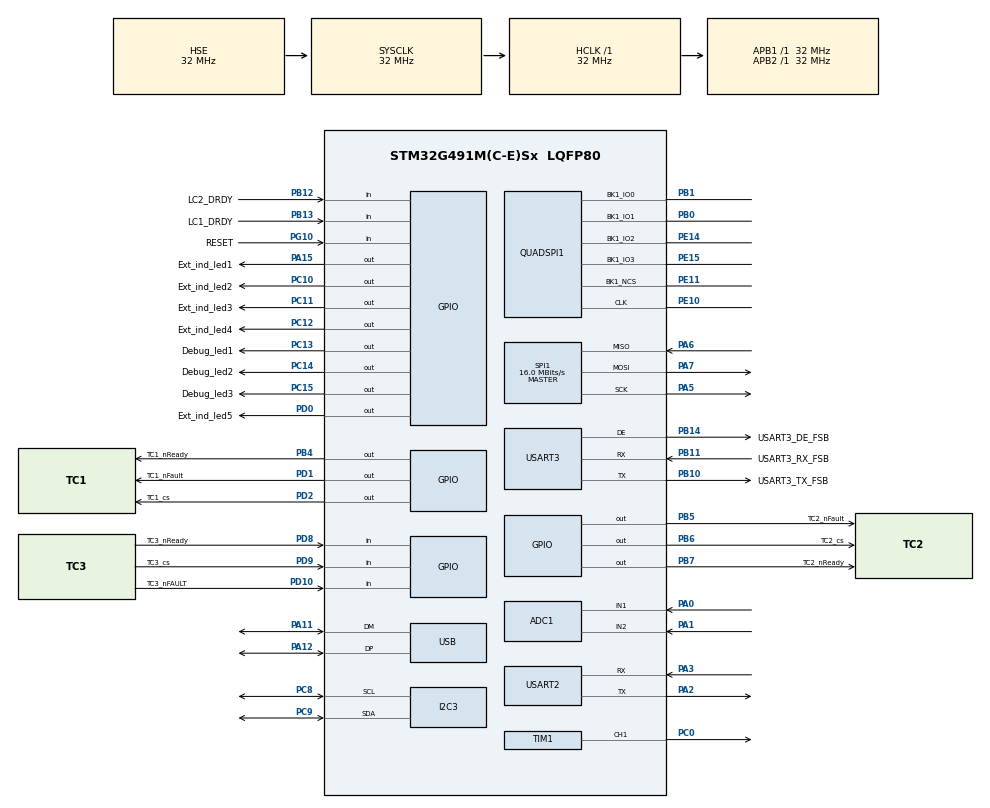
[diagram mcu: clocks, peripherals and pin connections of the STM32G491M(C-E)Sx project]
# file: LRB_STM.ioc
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ADC1.Channel-0\#ChannelRegularConversion=ADC_CHANNEL_1
ADC1.NbrOfConversionFlag=1
ADC1.OffsetNumber-0\#ChannelRegularConversion=ADC_OFFSET_NONE
ADC1.Rank-0\#ChannelRegularConversion=1
ADC1.SamplingTime-0\#ChannelRegularConversion=ADC_SAMPLETIME_2CYCLES_5
ADC1.SingleDiff-0\#ChannelRegularConversion=ADC_DIFFERENTIAL_ENDED
ADC1.master=1
I2C3.Timing=0x00B07CB4
Mcu.Family=STM32G4
Mcu.Name=STM32G491M(C-E)Sx
Mcu.Package=LQFP80
NVIC.PriorityGroup=NVIC_PRIORITYGROUP_4
PA0.Mode=IN1-Differential
PA0.Signal=ADC1_IN1
PA1.Mode=IN1-Differential
PA1.Signal=ADC1_IN2
PA11.Mode=Device
PA11.Signal=USB_DM
PA12.Mode=Device
PA12.Signal=USB_DP
PA13.Mode=Trace_Asynchronous_SW
PA13.Signal=SYS_JTMS-SWDIO
PA14.Mode=Trace_Asynchronous_SW
PA14.Signal=SYS_JTCK-SWCLK
PA15.GPIO_Label=Ext_ind_led1
PA15.Signal=GPIO_Output
PA2.Mode=Asynchronous
PA2.Signal=USART2_TX
PA3.Mode=Asynchronous
PA3.Signal=USART2_RX
PA5.Mode=Full_Duplex_Master
PA5.Signal=SPI1_SCK
PA6.Mode=Full_Duplex_Master
PA6.Signal=SPI1_MISO
PA7.Mode=Full_Duplex_Master
PA7.Signal=SPI1_MOSI
PB0.Mode=Single Bank 1
PB0.Signal=QUADSPI1_BK1_IO1
PB1.Mode=Single Bank 1
PB1.Signal=QUADSPI1_BK1_IO0
PB10.GPIO_Label=USART3_TX_FSB
PB10.Mode=Asynchronous
PB10.Signal=USART3_TX
PB11.GPIO_Label=USART3_RX_FSB
PB11.Mode=Asynchronous
PB11.Signal=USART3_RX
PB12.GPIO_Label=LC2_DRDY
PB12.Signal=GPIO_Input
PB13.GPIO_Label=LC1_DRDY
PB13.Signal=GPIO_Input
PB14.GPIO_Label=USART3_DE_FSB
PB14.Mode=Hardware Flow Control (RS485)
PB14.Signal=USART3_DE
PB3.Mode=Trace_Asynchronous_SW
PB3.Signal=SYS_JTDO-SWO
PB4.GPIO_Label=TC1_nReady
PB4.Signal=GPIO_Output
PB5.GPIO_Label=TC2_nFault
PB5.Signal=GPIO_Output
PB6.GPIO_Label=TC2_cs
PB6.Signal=GPIO_Output
PB7.GPIO_Label=TC2_nReady
PB7.Signal=GPIO_Output
PC0.Signal=S_TIM1_CH1
PC10.GPIO_Label=Ext_ind_led2
PC10.Signal=GPIO_Output
PC11.GPIO_Label=Ext_ind_led3
PC11.Signal=GPIO_Output
PC12.GPIO_Label=Ext_ind_led4
PC12.Signal=GPIO_Output
PC13.GPIO_Label=Debug_led1
PC13.Signal=GPIO_Output
PC14-OSC32_IN.GPIO_Label=Debug_led2
PC14-OSC32_IN.Signal=GPIO_Output
PC15-OSC32_OUT.GPIO_Label=Debug_led3
PC15-OSC32_OUT.Signal=GPIO_Output
PC8.Mode=I2C
PC8.Signal=I2C3_SCL
PC9.Mode=I2C
PC9.Signal=I2C3_SDA
PD0.GPIO_Label=Ext_ind_led5
PD0.Signal=GPIO_Output
PD1.GPIO_Label=TC1_nFault
PD1.Signal=GPIO_Output
PD10.GPIO_Label=TC3_nFAULT
PD10.Signal=GPIO_Input
PD2.GPIO_Label=TC1_cs
PD2.Signal=GPIO_Output
PD8.GPIO_Label=TC3_nReady
PD8.Signal=GPIO_Input
PD9.GPIO_Label=TC3_cs
PD9.Signal=GPIO_Input
PE10.Mode=Single Bank 1
PE10.Signal=QUADSPI1_CLK
PE11.Mode=Single Bank 1
PE11.Signal=QUADSPI1_BK1_NCS
PE14.Mode=Single Bank 1
PE14.Signal=QUADSPI1_BK1_IO2
PE15.Mode=Single Bank 1
PE15.Signal=QUADSPI1_BK1_IO3
PF0-OSC_IN.Mode=HSE-External-Oscillator
PF0-OSC_IN.Signal=RCC_OSC_IN
PF1-OSC_OUT.Mode=HSE-External-Oscillator
PF1-OSC_OUT.Signal=RCC_OSC_OUT
PG10-NRST.GPIO_Label=RESET
PG10-NRST.Signal=GPIO_Input
ProjectManager.HeapSize=0x200
ProjectManager.StackSize=0x400
ProjectManager.TargetToolchain=STM32CubeIDE
RCC.ADC12Freq_Value=32000000
RCC.ADC345Freq_Value=32000000
RCC.AHBFreq_Value=32000000
RCC.APB1Freq_Value=32000000
RCC.APB1TimFreq_Value=32000000
RCC.APB2Freq_Value=32000000
RCC.APB2TimFreq_Value=32000000
RCC.CortexFreq_Value=32000000
RCC.EXTERNAL_CLOCK_VALUE=12288000
RCC.HCLKFreq_Value=32000000
RCC.HSE_VALUE=32000000
RCC.HSI48_VALUE=48000000
RCC.HSI_VALUE=16000000
RCC.LSE_VALUE=32768
RCC.PLLSourceVirtual=RCC_PLLSOURCE_HSE
RCC.SYSCLKFreq_VALUE=32000000
RCC.SYSCLKSource=RCC_SYSCLKSOURCE_HSE
RCC.VCOOutputFreq_Value=256000000
SH.S_TIM1_CH1.0=TIM1_CH1,PWM Generation1 CH1
SPI1.CalculateBaudRate=16.0 MBits/s
SPI1.Direction=SPI_DIRECTION_2LINES
SPI1.Mode=SPI_MODE_MASTER
SPI1.VirtualType=VM_MASTER
TIM1.Channel-PWM\ Generation1\ CH1=TIM_CHANNEL_1
USART2.VirtualMode-Asynchronous=VM_ASYNC
USART3.VirtualMode-Asynchronous=VM_ASYNC
USART3.VirtualMode-Hardware\ Flow\ Control\ (RS485)=VM_ASYNC
VP_SYS_VS_DBSignals.Mode=DisableDeadBatterySignals
board=custom

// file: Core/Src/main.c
/* USER CODE BEGIN Header */
/**
  ******************************************************************************
  * @file           : main.c
  * @brief          : Main program body
  ******************************************************************************
  * @attention
  *
  * Copyright (c) 2026 STMicroelectronics.
  * All rights reserved.
  *
  * This software is licensed under terms that can be found in the LICENSE file
  * in the root directory of this software component.
  * If no LICENSE file comes with this software, it is provided AS-IS.
  *
  ******************************************************************************
  */
/* USER CODE END Header */
#include "main.h"
#include "adc.h"
#include "i2c.h"
#include "quadspi.h"
#include "spi.h"
#include "tim.h"
#include "usart.h"
#include "usb.h"
#include "gpio.h"

void SystemClock_Config(void);

int main(void)
{

  /* MCU Configuration--------------------------------------------------------*/

  /* Reset of all peripherals, Initializes the Flash interface and the Systick. */
  HAL_Init();

  /* Configure the system clock */
  SystemClock_Config();

  /* Initialize all configured peripherals */
  MX_GPIO_Init();
  MX_QUADSPI1_Init();
  MX_SPI1_Init();
  MX_USB_PCD_Init();
  MX_USART2_UART_Init();
  MX_USART3_UART_Init();
  MX_ADC1_Init();
  MX_I2C3_Init();
  MX_TIM1_Init();

  /* Infinite loop */
  /* USER CODE BEGIN WHILE */
  HAL_GPIO_WritePin(Ext_ind_led1_GPIO_Port, Ext_ind_led1_Pin, GPIO_PIN_SET);
  HAL_GPIO_WritePin(Ext_ind_led2_GPIO_Port, Ext_ind_led2_Pin, GPIO_PIN_SET);
  HAL_GPIO_WritePin(Ext_ind_led3_GPIO_Port, Ext_ind_led3_Pin, GPIO_PIN_SET);
  HAL_GPIO_WritePin(Ext_ind_led4_GPIO_Port, Ext_ind_led4_Pin, GPIO_PIN_SET);
  HAL_GPIO_WritePin(Ext_ind_led5_GPIO_Port, Ext_ind_led5_Pin, GPIO_PIN_SET);

  HAL_GPIO_WritePin(Debug_led1_GPIO_Port, Debug_led1_Pin, GPIO_PIN_SET);
  while (1)
  {
    /* USER CODE END WHILE */

  }
}

void SystemClock_Config(void)
{
  RCC_OscInitTypeDef RCC_OscInitStruct = {0};
  RCC_ClkInitTypeDef RCC_ClkInitStruct = {0};

  /** Configure the main internal regulator output voltage
  */
  HAL_PWREx_ControlVoltageScaling(PWR_REGULATOR_VOLTAGE_SCALE1);

  /** Initializes the RCC Oscillators according to the specified parameters
  * in the RCC_OscInitTypeDef structure.
  */
  RCC_OscInitStruct.OscillatorType = RCC_OSCILLATORTYPE_HSI48|RCC_OSCILLATORTYPE_HSE;
  RCC_OscInitStruct.HSEState = RCC_HSE_ON;
  RCC_OscInitStruct.HSI48State = RCC_HSI48_ON;
  RCC_OscInitStruct.PLL.PLLState = RCC_PLL_NONE;
  if (HAL_RCC_OscConfig(&RCC_OscInitStruct) != HAL_OK)
  {
    Error_Handler();
  }

  /** Initializes the CPU, AHB and APB buses clocks
  */
  RCC_ClkInitStruct.ClockType = RCC_CLOCKTYPE_HCLK|RCC_CLOCKTYPE_SYSCLK
                              |RCC_CLOCKTYPE_PCLK1|RCC_CLOCKTYPE_PCLK2;
  RCC_ClkInitStruct.SYSCLKSource = RCC_SYSCLKSOURCE_HSE;
  RCC_ClkInitStruct.AHBCLKDivider = RCC_SYSCLK_DIV1;
  RCC_ClkInitStruct.APB1CLKDivider = RCC_HCLK_DIV1;
  RCC_ClkInitStruct.APB2CLKDivider = RCC_HCLK_DIV1;

  if (HAL_RCC_ClockConfig(&RCC_ClkInitStruct, FLASH_LATENCY_1) != HAL_OK)
  {
    Error_Handler();
  }
}

void Error_Handler(void)
{
  __disable_irq();
  while (1)
  {
  }
}
